# S1C31W74 register map
Vendor: Epson; Series: S1C31W74; File version: 1.11
ARM 32-bit Cortex-M0 plus Microcontroller based device, CPU clock up to 24.8MHz
CPU: CM0PLUS r0p1, little endian, MPU, no FPU, VTOR, 2 interrupt priority bits
Registers are 16-bit, read-write, reset 0x0 unless marked. A register's access mark holds for its fields unless they carry their own. Offsets are from the block's base; lines under a group give offsets from that group; [hi:lo] are bit positions; {n}, {i} and the like mark numbered series; 'fields as' and 'values as' point back to an identical list; <NAME> marks a mode.

## Memory map
0x20400000 USB size 0x105 — USB Controller
0x40000000 SYS size 0x2 — Register write protection and RAM test registers
0x40000020 PWGA size 0x2 — Operation mode and voltage control
0x40000040 CLG size 0x12 — Clock sources control and clock supply management
0x40000080 CACHE size 0x2 — Cache controller
0x400000A0 WDT2 size 0x6 — Watchdog 2 timer counter, clock source and clock division ratio control
0x400000C0 RTCA size 0x14 — Real-time clock control
0x40000100 SVD2_0 size 0x8 — Supply voltage detector control
0x40000160 T16_0 size 0xE — 16 Timer / Counter, counting up or down from different sources
0x400001B0 FLASHC size 0x2 — Flash controller
0x40000200 PPORT size 0xE4 — I/O Ports control
0x40000300 UPMUX size 0x20 — Universal port multiplexer control
0x40000380 UART2_0 size 0x14 — UART2 channel 0 control
0x400003A0 T16_1 size 0xE
0x400003B0 SPIA_0 size 0x10 — Synchronous serial interface control
0x400003C0 I2C_0 size 0x18 — I2C channel 0 control
0x40000400 T16B_0 size 0x1E — 16-bit PWM timer channel 0 comparator/capture control
0x40000440 T16B_1 size 0x1E — 16-bit PWM timer channel 1 comparator/capture control
0x40000480 T16_3 size 0xE
0x40000600 UART2_1 size 0x14 — UART2 channel 1 control
0x40000680 T16_2 size 0xE
0x40000690 QSPI_0 size 0x1A — Quad Synchronous Serial Interface channel 0
0x400006C0 I2C_1 size 0x18 — I2C channel 1 control
0x40000700 SNDA size 0xE — SNDA Sound generatior
0x40000720 REMC2 size 0x14 — IR Remote Controller
0x40000800 LCD32B size 0x14 — LCD Driver control
0x40000840 RFC_0 size 0x12
0x40000970 USBMISC size 0x8 — USB MISC Controller
0x40000980 SVD2_1 size 0x8
0x40001000 DMAC size 0x1018 — PrimeCell uDMA Controller

## Interrupts
0 DMAC
1 SVD2_0
2 PORT (PPORT)
3 CLG
4 RTC (RTCA)
5 T16_0
6 UART2_0
7 T16_1
8 SPIA_0
9 I2C_0
10 T16B_0
11 T16B_1
12 UART2_1
13 T16_2
14 QSPI_0
15 I2C_1
16 REMC2
17 LCD (LCD32B)
18 T16_3
19 USB
20 SVD2_1
21 SNDA
22 RFC_0

## SYS — Register write protection and RAM test registers
Base 0x40000000
0x00 PROT — Register Write Protect Register
  [15:0] PROT — Register write protect

## PWGA — Operation mode and voltage control
Base 0x40000020
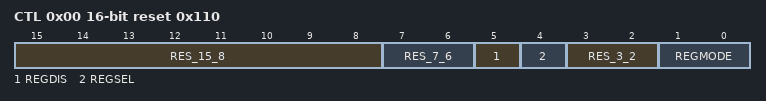
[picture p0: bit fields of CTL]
0x00 CTL reset 0x110 — Control Register
  [15:8] RES_15_8 ro — Reserved bits
  [7:6] RES_7_6 ro — Reserved bits
  [5] REGDIS — Regulator discharge enable (can be write protected)
    0=NORMAL (Normal operation); 1=DISCHARGE (Regulator discharge)
  [4] REGSEL — Regulator voltage select (can be write protected)
    0=1_2V; 1=1_8V
  [3:2] RES_3_2 ro — Reserved bits
  [1:0] REGMODE — Regulator operation mode select (can be write protected)
    0=AUTO (Automatic mode); 2=NORM (Normal mode); 3=ECON (Economy mode)

## CACHE — Cache controller
Base 0x40000080
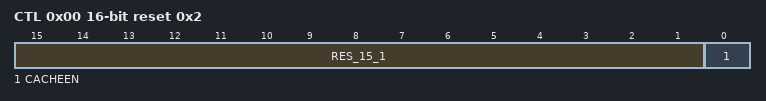
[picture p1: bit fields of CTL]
0x00 CTL reset 0x2 — Cache Control Register
  [15:1] RES_15_1 ro — Reserved bits
  [0] CACHEEN — Cache enable
    0=DISABLE (Disable (Also refer to VALID_BIT_RST_DIS)); 1=ENABLE

## WDT2 — Watchdog 2 timer counter, clock source and clock division ratio control
Base 0x400000A0
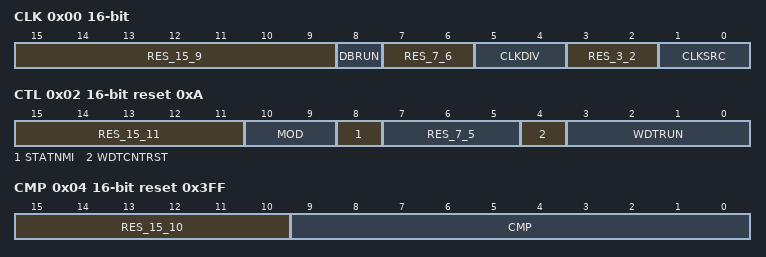
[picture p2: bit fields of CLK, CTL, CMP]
0x00 CLK — Clock Control Register
  [15:9] RES_15_9 ro — Reserved bits
  [8] DBRUN — Enable clock on debug mode (can be write protected)
    0=DISABLE; 1=ENABLE
  [7:6] RES_7_6 ro — Reserved bits
  [5:4] CLKDIV — Clock division select (can be write protected)
  [3:2] RES_3_2 ro — Reserved bits
  [1:0] CLKSRC — Clock source select (can be write protected)
    0=IOSC; 1=OSC1; 2=OSC3; 3=EXOSC
0x02 CTL reset 0xA — Control Register
  [15:11] RES_15_11 ro — Reserved bits
  [10:9] MOD — WDT2 operating mode (can be write protected)
    0=RESET (Reset mode); 1=NMI (NMI mode); 2=RESET_AFTER_NMI (Reset after NMI mode)
  [8] STATNMI ro — Counter overflow and NMI status
    0=NO_NMI (NMI not occurred); 1=NMI (NMI (counter overflow) occurred)
  [7:5] RES_7_5 ro — Reserved bits
  [4] WDTCNTRST — WDT2 counter reset (can be write protected)
    0=IGNORED; 1=RESET
  [3:0] WDTRUN — WDT2 run and stop control (can be write protected)
    10=STOP
0x04 CMP reset 0x3FF — Counter Compare Match Register
  [15:10] RES_15_10 ro — Reserved bits
  [9:0] CMP — WDT2 Compare Match (can be write protected)

## Licence text in the file
Copyright (C) SEIKO EPSON CORPORATION 2016. All rights reserved.
